AUTOSAR XML (schema 00049)
package /Application/DltConfig
  dlt log channel to process mapping DltLogChannelToProcessMapping_SOA_ROA_TO_SOA_ROA: dlt-log-channel=SOA_ROA, process=SOA_ROA
package /Application/Executable
  executable SOA_ROA: category=APPLICATION_LEVEL, logging-behavior=USES-LOGGING, reporting-behavior=REPORTS-EXECUTION-STATE, version=1.0.0
    root sw component prototype AA: application-type=SOA_ROA
package /Application/Manifest
  service instance to port prototype mapping SOA_ROA_AA_PPort_SOA_ROA: port-prototype=AA.PPort_SOA_ROA, process=SOA_ROA, service-instance=Provider_SoaRoa
  service instance to port prototype mapping SOA_ROA_AA_RPort_Zone1VehicleInfo: port-prototype=AA.RPort_Zone1VehicleInfo, process=SOA_ROA, service-instance=Consumer_SoaRoa_VehicleInfo
  service instance to port prototype mapping SOA_ROA_AA_RPort_Zone2Roa: port-prototype=AA.RPort_Zone2Roa, process=SOA_ROA, service-instance=Consumer_Zone2Roa
package /Application/Package/SOA_ROA/SoftwareCluster_1_0_0
  software cluster SOA_ROA_SoftwareCluster: category=APPLICATION_LAYER, contained-ar-element=SOA_ROA, contained-package-element=[SOA_ROA_AA_PPort_SOA_ROA, SOA_ROA_AA_RPort_Zone2Roa], contained-process=SOA_ROA, vendor-id=79, vendor-signature=ParaCertificate, version=1.0.0
package /Application/Package/SOA_ROA/SoftwareCluster_1_0_1
  software cluster SOA_ROA_SoftwareCluster: category=APPLICATION_LAYER, contained-ar-element=SOA_ROA, contained-package-element=[SOA_ROA_AA_PPort_SOA_ROA, SOA_ROA_AA_RPort_Zone2Roa], contained-process=SOA_ROA, vendor-id=79, vendor-signature=ParaCertificate, version=1.0.1
package /Application/Package/SOA_ROA/SoftwareCluster_1_0_2
  software cluster SOA_ROA_SoftwareCluster: category=APPLICATION_LAYER, contained-ar-element=SOA_ROA, contained-package-element=[SOA_ROA_AA_PPort_SOA_ROA, SOA_ROA_AA_RPort_Zone2Roa], contained-process=SOA_ROA, vendor-id=79, vendor-signature=ParaCertificate, version=1.0.2
package /Application/Package/SOA_ROA/SoftwarePackage
  software package SOA_ROA_InstallSoftwarePackage_1_0_0: action-type=INSTALL, compressed-software-package-size=0, maximum-supported-ucm-version=1.0.0, minimum-supported-ucm-version=1.0.0, packager-id=79, packager-signature=ParaCertificate, post-verification-reboot=false, pre-activate=SC.Off, pre-activation-reboot=false, software-cluster=SoftwareCluster_1_0_0/SOA_ROA_SoftwareCluster, uncompressed-software-cluster-size=0, verify=SC.Verify
  software package SOA_ROA_RemoveSoftwarePackage_1_0_2: action-type=REMOVE, compressed-software-package-size=0, maximum-supported-ucm-version=1.0.0, minimum-supported-ucm-version=1.0.0, packager-id=79, packager-signature=ParaCertificate, post-verification-reboot=false, pre-activate=SC.Off, pre-activation-reboot=false, software-cluster=SoftwareCluster_1_0_2/SOA_ROA_SoftwareCluster, uncompressed-software-cluster-size=0, verify=SC.Verify
  software package SOA_ROA_UpdateSoftwarePackage_1_0_1: action-type=UPDATE, compressed-software-package-size=0, maximum-supported-ucm-version=1.0.0, minimum-supported-ucm-version=1.0.0, packager-id=79, packager-signature=ParaCertificate, post-verification-reboot=false, pre-activate=SC.Off, pre-activation-reboot=false, software-cluster=SoftwareCluster_1_0_1/SOA_ROA_SoftwareCluster, uncompressed-software-cluster-size=0, verify=SC.Verify
package /Application/Package/SOA_ROA/VehiclePackage
  vehicle package SOA_ROA_InstallVehiclePackage_1_0_0: vehicle-driver-notification{approval-required=true, notification-state=PROCESS}, packager-signature=ParaCertificate
    rollout-qualifications:
      vehicle rollout step RolloutQualification0
        ucm-processings:
          ucm step UcmProcessing0: ucm=SOA_ROA_InstallVehiclePackage_1_0_0/EEVP_UCM
            software package step SoftwarePackageStep0: process=SOA_ROA_InstallSoftwarePackage_1_0_0, transfers=software-package-storing={storing=UCM, transfer=SOA_ROA_InstallSoftwarePackage_1_0_0}
    ucm description EEVP_UCM: identifier=EEVP_UCM
  vehicle package SOA_ROA_RemoveVehiclePackage_1_0_2: vehicle-driver-notification{approval-required=true, notification-state=PROCESS}, packager-signature=ParaCertificate
    rollout-qualifications:
      vehicle rollout step RolloutQualification0
        ucm-processings:
          ucm step UcmProcessing0: ucm=SOA_ROA_RemoveVehiclePackage_1_0_2/EEVP_UCM
            software package step SoftwarePackageStep0: process=SOA_ROA_RemoveSoftwarePackage_1_0_2, transfers=software-package-storing={storing=UCM, transfer=SOA_ROA_RemoveSoftwarePackage_1_0_2}
    ucm description EEVP_UCM: identifier=EEVP_UCM
  vehicle package SOA_ROA_UpdateVehiclePackage_1_0_1: vehicle-driver-notification{approval-required=true, notification-state=PROCESS}, packager-signature=ParaCertificate
    rollout-qualifications:
      vehicle rollout step RolloutQualification0
        ucm-processings:
          ucm step UcmProcessing0: ucm=SOA_ROA_UpdateVehiclePackage_1_0_1/EEVP_UCM
            software package step SoftwarePackageStep0: process=SOA_ROA_UpdateSoftwarePackage_1_0_1, transfers=software-package-storing={storing=UCM, transfer=SOA_ROA_UpdateSoftwarePackage_1_0_1}
    ucm description EEVP_UCM: identifier=EEVP_UCM
package /Application/Process
  process SOA_ROA: executable=SOA_ROA, state-dependent-startup-config{function-group-state=[SC.On, SC.Verify], resource-group=DefaultResourceGroup, startup-config=SOA}
    process state machine SOA_ROA: type=ProcessState
package /Application/SwComponent
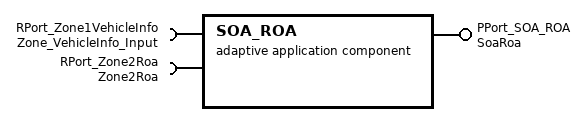
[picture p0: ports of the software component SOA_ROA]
  adaptive application sw component type SOA_ROA
    provide port PPort_SOA_ROA: provided-interface=SoaRoa
    require port RPort_Zone1VehicleInfo: required-interface=Zone_VehicleInfo_Input
    require port RPort_Zone2Roa: required-interface=Zone2Roa
